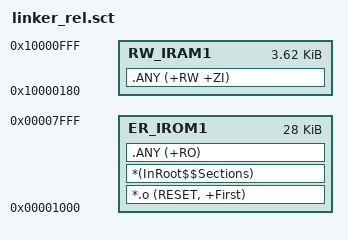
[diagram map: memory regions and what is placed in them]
; *************************************************************
; *** Scatter-Loading Description File generated by uVision ***
; *************************************************************

LR_IROM1 0x00001000 0x00007000  {    ; load region size_region
  ER_IROM1 0x00001000 0x00007000  {  ; load address = execution address
   *.o (RESET, +First)
   *(InRoot$$Sections)
   .ANY (+RO)
  }
  RW_IRAM1 0x10000180 0x00000E80  {  ; RW data
   .ANY (+RW +ZI)
  }
}
